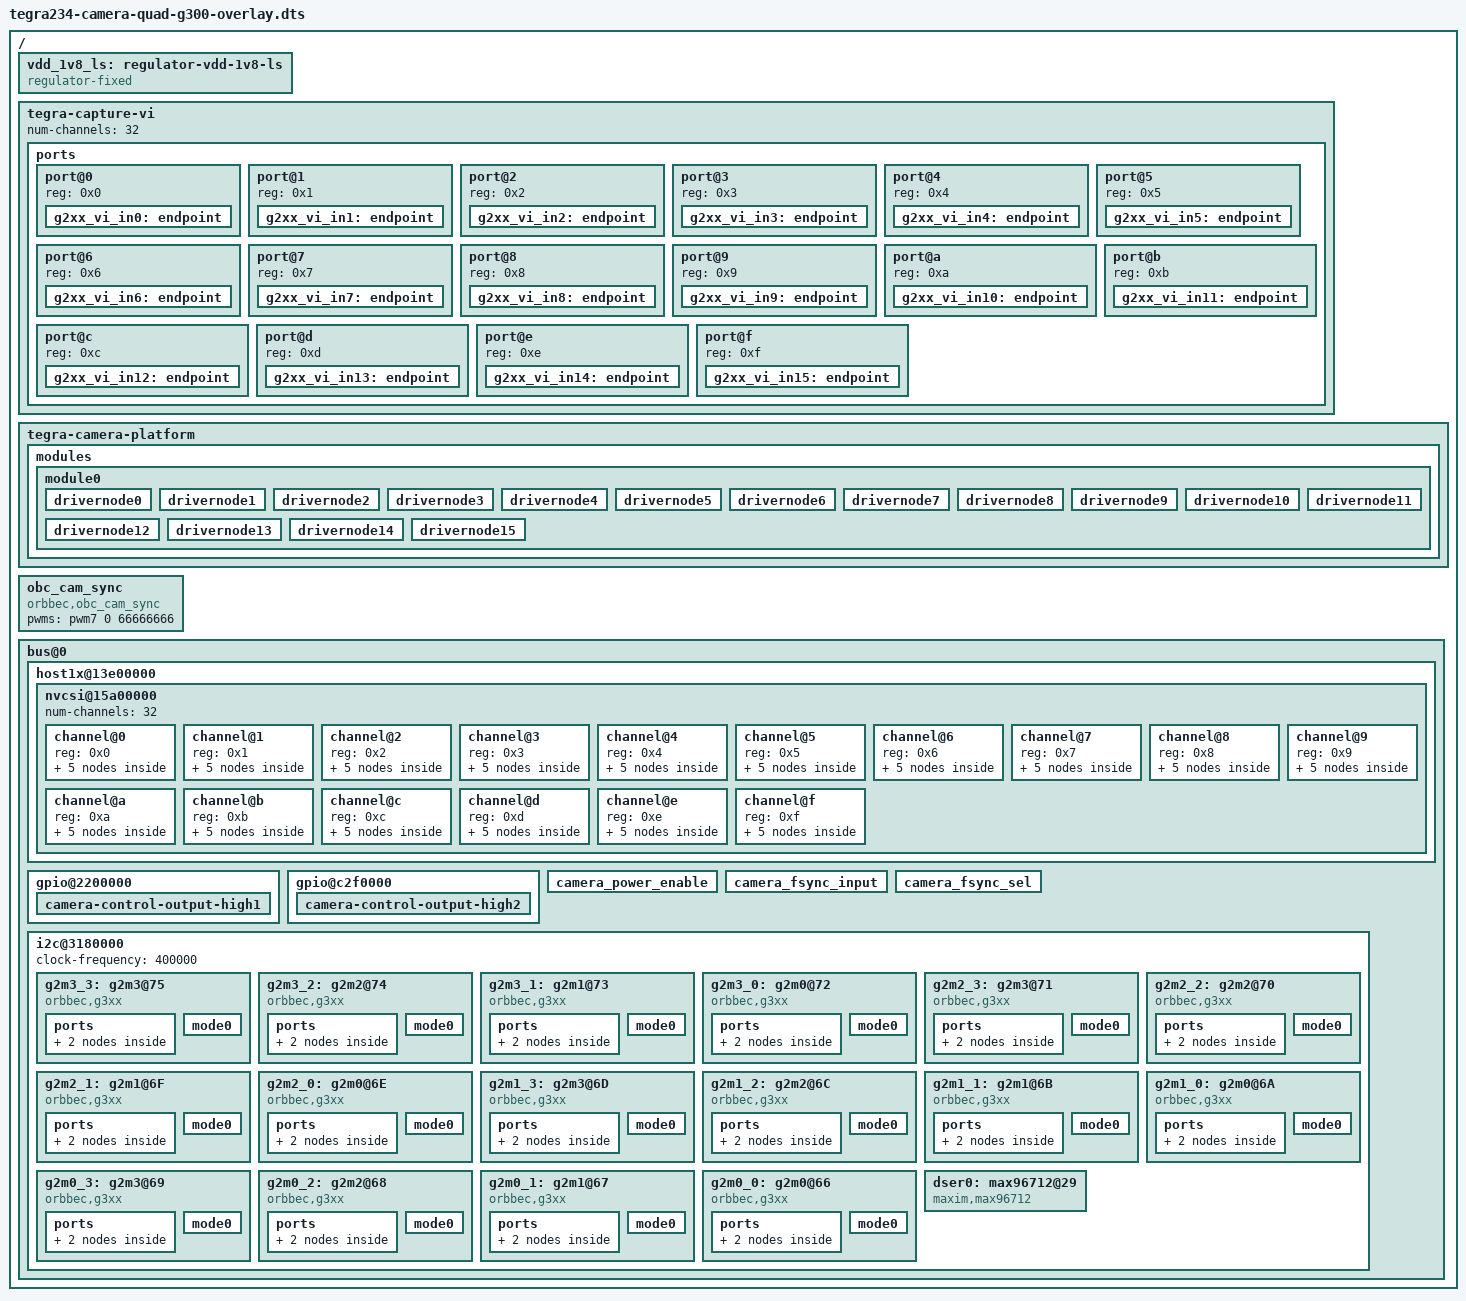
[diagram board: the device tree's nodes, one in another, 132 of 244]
// SPDX-License-Identifier: GPL-2.0-only
// SPDX-FileCopyrightText: Copyright (c) 2024-2029, Orbbec CORPORATION.  All rights reserved.


#include <dt-bindings/clock/tegra234-clock.h>
#include <dt-bindings/gpio/tegra234-gpio.h>
#include <dt-bindings/tegra234-p3767-0000-common.h>
#include <dt-bindings/pinctrl/pinctrl-tegra.h>
//MFP9 TEGRA234 MAIN GPIO(AC，0)
//MFP10  TEGRA234 MAIN GPIO(Z，7)
//MPP2   TEGRA_AON_GPIO(G, 6)

#define CAM0_RST_L	TEGRA234_AON_GPIO(CC, 3)
#define CAM0_PWDN   TEGRA234_MAIN_GPIO(H, 6)
#define PWR_EN      TEGRA234_MAIN_GPIO(AC, 7)
#define SYNC_OUT   	TEGRA234_MAIN_GPIO(G, 6)
#define SYNC_IN    	TEGRA234_MAIN_GPIO(AC, 4) //
#define SYNC_SEL   	TEGRA234_MAIN_GPIO(AC, 2)
#define PPS_TRIGGER	TEGRA234_MAIN_GPIO(AC, 0) //
#define CAMERA_I2C_MUX_BUS(x) (0x1E + x)
/{
	vdd_1v8_ls: regulator-vdd-1v8-ls {
			compatible = "regulator-fixed";
			regulator-name = "VDD_1V8_LS";
			regulator-min-microvolt = <1800000>;
			regulator-max-microvolt = <1800000>;
			regulator-always-on;
	};


	/* Orbbec Camera configuration */
	tegra-capture-vi {
		num-channels = <32>;
		ports {
			status = "okay";
			#address-cells = <1>;
			#size-cells = <0>;

			port@0 {
				reg = <0x0>;
				status = "okay";
				g2xx_vi_in0: endpoint {
					status = "okay";
					vc-id = <0>;
					port-index = <0>; //0
					bus-width = <2>;
					remote-endpoint = <&g2xx_csi_out0>;
				};
			};
			port@1 {
				reg = <0x1>;
				status = "okay";
				g2xx_vi_in1: endpoint {
					status = "okay";
					vc-id = <1>;
					port-index = <0>; //0
					bus-width = <2>;
					remote-endpoint = <&g2xx_csi_out1>;
				};
			};
			port@2 {
				reg = <0x2>;
				status = "okay";
				g2xx_vi_in2: endpoint {
					status = "okay";
					vc-id = <2>;
					port-index = <0>; //0
					bus-width = <2>;
					remote-endpoint = <&g2xx_csi_out2>;
				};
			};
			port@3 {
				reg = <0x3>;
				status = "okay";
				g2xx_vi_in3: endpoint {
					status = "okay";
					vc-id = <3>;
					port-index = <0>; //0
					bus-width = <2>;
					remote-endpoint = <&g2xx_csi_out3>;
				};
			};

			port@4 {
				reg = <0x4>;
				status = "okay";
				g2xx_vi_in4: endpoint {
					status = "okay";
					vc-id = <2>;
					port-index = <1>; //1
					bus-width = <2>;
					remote-endpoint = <&g2xx_csi_out4>;
				};
			};
			port@5 {
				reg = <0x5>;
				status = "okay";
				g2xx_vi_in5: endpoint {
					status = "okay";
					vc-id = <3>;
					port-index = <1>; //1
					bus-width = <2>;
					remote-endpoint = <&g2xx_csi_out5>;
				};
			};
			port@6 {
				reg = <0x6>;
				status = "okay";
				g2xx_vi_in6: endpoint {
					status = "okay";
					vc-id = <0>;
					port-index = <1>; //1
					bus-width = <2>;
					remote-endpoint = <&g2xx_csi_out6>;
				};
			};
			port@7 {
				reg = <0x7>;
				status = "okay";
				g2xx_vi_in7: endpoint {
					status = "okay";
					vc-id = <1>;
					port-index = <1>; //1
					bus-width = <2>;
					remote-endpoint = <&g2xx_csi_out7>;
				};
			};

			port@8 {
				reg = <0x8>;
				status = "okay";
				g2xx_vi_in8: endpoint {
					status = "okay";
					vc-id = <0>;
					port-index = <2>; //2
					bus-width = <2>;
					remote-endpoint = <&g2xx_csi_out8>;
				};
			};
			port@9 {
				reg = <0x9>;
				status = "okay";
				g2xx_vi_in9: endpoint {
					status = "okay";
					vc-id = <1>;
					port-index = <2>; //2
					bus-width = <2>;
					remote-endpoint = <&g2xx_csi_out9>;
				};
			};
			port@a {
				reg = <0xa>;
				status = "okay";
				g2xx_vi_in10: endpoint {
					status = "okay";
					vc-id = <2>;
					port-index = <2>; //2
					bus-width = <2>;
					remote-endpoint = <&g2xx_csi_out10>;
				};
			};
			port@b {
				reg = <0xb>;
				status = "okay";
				g2xx_vi_in11: endpoint {
					status = "okay";
					vc-id = <3>;
					port-index = <2>; //2
					bus-width = <2>;
					remote-endpoint = <&g2xx_csi_out11>;
				};
			};

			port@c {
				reg = <0xc>;
				status = "okay";
				g2xx_vi_in12: endpoint {
					status = "okay";
					vc-id = <2>;
					port-index = <3>; //3
					bus-width = <2>;
					remote-endpoint = <&g2xx_csi_out12>;
				};
			};

			port@d {
				reg = <0xd>;
				status = "okay";
				g2xx_vi_in13: endpoint {
					status = "okay";
					vc-id = <3>;
					port-index = <3>; //3
					bus-width = <2>;
					remote-endpoint = <&g2xx_csi_out13>;
				};
			};
			port@e {
				reg = <0xe>;
				status = "okay";
				g2xx_vi_in14: endpoint {
					status = "okay";
					vc-id = <0>;
					port-index = <3>; //3
					bus-width = <2>;
					remote-endpoint = <&g2xx_csi_out14>;
				};
			};
			port@f {
				reg = <0xf>;
				status = "okay";
				g2xx_vi_in15: endpoint {
					status = "okay";
					vc-id = <1>;
					port-index = <3>; //3
					bus-width = <2>;
					remote-endpoint = <&g2xx_csi_out15>;
				};
			};
		};
	};

	tegra-camera-platform {
		#if 0
		compatible = "nvidia, tegra-camera-platform";
		num_csi_lanes = <16>;
		max_lane_speed = <20000000>;
		min_bits_per_pixel = <8>;
		vi_peak_byte_per_pixel = <2>;
		vi_bw_margin_pct = <25>;
		isp_peak_byte_per_pixel = <5>;
		isp_bw_margin_pct = <25>;
		#endif
		modules {
			status = "okay";
			module0 {
				status = "okay";
				badge = "g2xx_0";
				position = "bottomleft";
				orientation = "1";

				drivernode0 {
					status = "okay";
					/* Declare PCL support driver (classically known as guid)  */
					pcl_id = "v4l2_sensor";
					/* Declare the device-tree hierarchy to driver instance */
					sysfs-device-tree = "/sys/firmware/devicetree/base/bus@0/i2c@3180000/g2m0@66";
				};

				drivernode1 {
					status = "okay";
					/* Declare PCL support driver (classically known as guid)  */
					pcl_id = "v4l2_sensor";
					/* Declare the device-tree hierarchy to driver instance */
					sysfs-device-tree = "/sys/firmware/devicetree/base/bus@0/i2c@3180000/g2m1@67";
				};

				drivernode2 {
					status = "okay";
					/* Declare PCL support driver (classically known as guid)  */
					pcl_id = "v4l2_sensor";
					/* Declare the device-tree hierarchy to driver instance */
					sysfs-device-tree = "/sys/firmware/devicetree/base/bus@0/i2c@3180000/g2m2@68";
				};

				drivernode3 {
					status = "okay";
					/* Declare PCL support driver (classically known as guid)  */
					pcl_id = "v4l2_sensor";
					/* Declare the device-tree hierarchy to driver instance */
					sysfs-device-tree = "/sys/firmware/devicetree/base/bus@0/i2c@3180000/g2m3@69";
				};

				drivernode4 {
					status = "okay";
					/* Declare PCL support driver (classically known as guid)  */
					pcl_id = "v4l2_sensor";
					/* Declare the device-tree hierarchy to driver instance */
					sysfs-device-tree = "/sys/firmware/devicetree/base/bus@0/i2c@3180000/g2m0@6A";
				};

				drivernode5 {
					status = "okay";
					/* Declare PCL support driver (classically known as guid)  */
					pcl_id = "v4l2_sensor";
					/* Declare the device-tree hierarchy to driver instance */
					sysfs-device-tree = "/sys/firmware/devicetree/base/bus@0/i2c@3180000/g2m1@6B";
				};

				drivernode6 {
					status = "okay";
					/* Declare PCL support driver (classically known as guid)  */
					pcl_id = "v4l2_sensor";
					/* Declare the device-tree hierarchy to driver instance */
					sysfs-device-tree = "/sys/firmware/devicetree/base/bus@0/i2c@3180000/g2m2@6C";
				};

				drivernode7 {
					status = "okay";
					/* Declare PCL support driver (classically known as guid)  */
					pcl_id = "v4l2_sensor";
					/* Declare the device-tree hierarchy to driver instance */
					sysfs-device-tree = "/sys/firmware/devicetree/base/bus@0/i2c@3180000/g2m3@6D";
				};

				drivernode8 {
					status = "okay";
					/* Declare PCL support driver (classically known as guid)  */
					pcl_id = "v4l2_sensor";
					/* Declare the device-tree hierarchy to driver instance */
					sysfs-device-tree = "/sys/firmware/devicetree/base/bus@0/i2c@3180000/g2m0@6E";
				};

				drivernode9 {
					status = "okay";
					/* Declare PCL support driver (classically known as guid)  */
					pcl_id = "v4l2_sensor";
					/* Declare the device-tree hierarchy to driver instance */
					sysfs-device-tree = "/sys/firmware/devicetree/base/bus@0/i2c@3180000/g2m1@6F";
				};

				drivernode10 {
					status = "okay";
					/* Declare PCL support driver (classically known as guid)  */
					pcl_id = "v4l2_sensor";
					/* Declare the device-tree hierarchy to driver instance */
					sysfs-device-tree = "/sys/firmware/devicetree/base/bus@0/i2c@3180000/g2m2@70";
				};

				drivernode11 {
					status = "okay";
					/* Declare PCL support driver (classically known as guid)  */
					pcl_id = "v4l2_sensor";
					/* Declare the device-tree hierarchy to driver instance */
					sysfs-device-tree = "/sys/firmware/devicetree/base/bus@0/i2c@3180000/g2m3@71";
				};

				drivernode12 {
					status = "okay";
					/* Declare PCL support driver (classically known as guid)  */
					pcl_id = "v4l2_sensor";
					/* Declare the device-tree hierarchy to driver instance */
					sysfs-device-tree = "/sys/firmware/devicetree/base/bus@0/i2c@3180000/g2m0@72";
				};

				drivernode13 {
					status = "okay";
					/* Declare PCL support driver (classically known as guid)  */
					pcl_id = "v4l2_sensor";
					/* Declare the device-tree hierarchy to driver instance */
					sysfs-device-tree = "/sys/firmware/devicetree/base/bus@0/i2c@3180000/g2m1@73";
				};

				drivernode14 {
					status = "okay";
					/* Declare PCL support driver (classically known as guid)  */
					pcl_id = "v4l2_sensor";
					/* Declare the device-tree hierarchy to driver instance */
					sysfs-device-tree = "/sys/firmware/devicetree/base/bus@0/i2c@3180000/g2m2@74";
				};

				drivernode15 {
					status = "okay";
					/* Declare PCL support driver (classically known as guid)  */
					pcl_id = "v4l2_sensor";
					/* Declare the device-tree hierarchy to driver instance */
					sysfs-device-tree = "/sys/firmware/devicetree/base/bus@0/i2c@3180000/g2m3@75";
				};
			};
		};
	};

	obc_cam_sync {
		compatible = "orbbec,obc_cam_sync";
		//sync-in-gpios = <&gpio SYNC_IN GPIO_ACTIVE_HIGH>;
		//sync-out-gpios = <&gpio_aon SYNC_OUT GPIO_ACTIVE_HIGH>;  //Use hrtimer to generate trigger signals
		pwms = <&pwm7 0 66666666>; //33333333>; //Use PWM to generate trigger signals, Default PWM mode, if use hrtimer comment out this line
	};
	bus@0 {
		/* NVCSI configuration */
		host1x@13e00000 {
			nvcsi@15a00000 {
				#address-cells = <1>;
				#size-cells = <0>;

				num-channels = <32>;

				channel@0 {
					reg = <0x0>;
					status = "okay";
					ports {
						status = "okay";
						#address-cells = <1>;
						#size-cells = <0>;
						port@0 {
							reg = <0>;
							status = "okay";
							g2xx_csi_in0: endpoint@0 {
								status = "okay";
								port-index = <0>; //0
								bus-width = <2>;
								remote-endpoint = <&g2m0_0_out>;
							};
						};
						port@1 {
							reg = <1>;
							status = "okay";
							g2xx_csi_out0: endpoint@1 {
								status = "okay";
								remote-endpoint = <&g2xx_vi_in0>;
							};
						};
					};
				};
				channel@1 {
					reg = <0x1>;
					status = "okay";
					ports {
						status = "okay";
						#address-cells = <1>;
						#size-cells = <0>;
						port@0 {
							reg = <0>;
							status = "okay";
							g2xx_csi_in1: endpoint@2 {
								status = "okay";
								port-index = <0>; //0
								bus-width = <2>;
								remote-endpoint = <&g2m0_1_out>;
							};
						};
						port@1 {
							reg = <1>;
							status = "okay";
							g2xx_csi_out1: endpoint@3 {
								status = "okay";
								remote-endpoint = <&g2xx_vi_in1>;
							};
						};
					};
				};
				channel@2 {
					reg = <0x2>;
					status = "okay";
					ports {
						status = "okay";
						#address-cells = <1>;
						#size-cells = <0>;
						port@0 {
							reg = <0>;
							status = "okay";
							g2xx_csi_in2: endpoint@4 {
								status = "okay";
								port-index = <0>; //0
								bus-width = <2>;
								remote-endpoint = <&g2m0_2_out>;
							};
						};
						port@1 {
							reg = <1>;
							status = "okay";
							g2xx_csi_out2: endpoint@5 {
								status = "okay";
								remote-endpoint = <&g2xx_vi_in2>;
							};
						};
					};
				};
				channel@3 {
					reg = <0x3>;
					status = "okay";
					ports {
						status = "okay";
						#address-cells = <1>;
						#size-cells = <0>;
						port@0 {
							reg = <0>;
							status = "okay";
							g2xx_csi_in3: endpoint@6 {
								status = "okay";
								port-index = <0>; //0
								bus-width = <2>;
								remote-endpoint = <&g2m0_3_out>;
							};
						};
						port@1 {
							reg = <1>;
							status = "okay";
							g2xx_csi_out3: endpoint@7 {
								status = "okay";
								remote-endpoint = <&g2xx_vi_in3>;
							};
						};
					};
				};

				channel@4 {
					reg = <0x4>;
					status = "okay";
					ports {
						status = "okay";
						#address-cells = <1>;
						#size-cells = <0>;
						port@0 {
							reg = <0>;
							status = "okay";
							g2xx_csi_in4: endpoint@8 {
								status = "okay";
								port-index = <1>; //1
								bus-width = <2>;
								remote-endpoint = <&g2m1_0_out>;
							};
						};
						port@1 {
							reg = <1>;
							status = "okay";
							g2xx_csi_out4: endpoint@9 {
								status = "okay";
								remote-endpoint = <&g2xx_vi_in4>;
							};
						};
					};
				};
				channel@5 {
					reg = <0x5>;
					status = "okay";
					ports {
						status = "okay";
						#address-cells = <1>;
						#size-cells = <0>;
						port@0 {
							reg = <0>;
							status = "okay";
							g2xx_csi_in5: endpoint@10 {
								status = "okay";
								port-index = <1>; //1
								bus-width = <2>;
								remote-endpoint = <&g2m1_1_out>;
							};
						};
						port@1 {
							reg = <1>;
							status = "okay";
							g2xx_csi_out5: endpoint@11 {
								status = "okay";
								remote-endpoint = <&g2xx_vi_in5>;
							};
						};
					};
				};
				channel@6 {
					reg = <0x6>;
					status = "okay";
					ports {
						status = "okay";
						#address-cells = <1>;
						#size-cells = <0>;
						port@0 {
							reg = <0>;
							status = "okay";
							g2xx_csi_in6: endpoint@12 {
								status = "okay";
								port-index = <1>; //1
								bus-width = <2>;
								remote-endpoint = <&g2m1_2_out>;
							};
						};
						port@1 {
							reg = <1>;
							status = "okay";
							g2xx_csi_out6: endpoint@13 {
								status = "okay";
								remote-endpoint = <&g2xx_vi_in6>;
							};
						};
					};
				};
				channel@7 {
					reg = <0x7>;
					status = "okay";
					ports {
						status = "okay";
						#address-cells = <1>;
						#size-cells = <0>;
						port@0 {
							reg = <0>;
							status = "okay";
							g2xx_csi_in7: endpoint@14 {
								status = "okay";
								port-index = <1>; //1
								bus-width = <2>;
								remote-endpoint = <&g2m1_3_out>;
							};
						};
						port@1 {
							reg = <1>;
							status = "okay";
							g2xx_csi_out7: endpoint@15 {
								status = "okay";
								remote-endpoint = <&g2xx_vi_in7>;
							};
						};
					};
				};

				channel@8 {
					reg = <0x8>;
					status = "okay";
					ports {
						status = "okay";
						#address-cells = <1>;
						#size-cells = <0>;
						port@0 {
							reg = <0>;
							status = "okay";
							g2xx_csi_in8: endpoint@16 {
								status = "okay";
								port-index = <2>; //2
								bus-width = <2>;
								remote-endpoint = <&g2m2_0_out>;
							};
						};
						port@1 {
							reg = <1>;
							status = "okay";
							g2xx_csi_out8: endpoint@17 {
								status = "okay";
								remote-endpoint = <&g2xx_vi_in8>;
							};
						};
					};
				};
				channel@9 {
					reg = <0x9>;
					status = "okay";
					ports {
						status = "okay";
						#address-cells = <1>;
						#size-cells = <0>;
						port@0 {
							reg = <0>;
							status = "okay";
							g2xx_csi_in9: endpoint@18 {
								status = "okay";
								port-index = <2>; //2
								bus-width = <2>;
								remote-endpoint = <&g2m2_1_out>;
							};
						};
						port@1 {
							reg = <1>;
							status = "okay";
							g2xx_csi_out9: endpoint@19 {
								status = "okay";
								remote-endpoint = <&g2xx_vi_in9>;
							};
						};
					};
				};
				channel@a {
					reg = <0xa>;
					status = "okay";
					ports {
						status = "okay";
						#address-cells = <1>;
						#size-cells = <0>;
						port@0 {
							reg = <0>;
							status = "okay";
							g2xx_csi_in10: endpoint@20 {
								status = "okay";
								port-index = <2>; //2
								bus-width = <2>;
								remote-endpoint = <&g2m2_2_out>;
							};
						};
						port@1 {
							reg = <1>;
							status = "okay";
							g2xx_csi_out10: endpoint@21 {
								status = "okay";
								remote-endpoint = <&g2xx_vi_in10>;
							};
						};
					};
				};
				channel@b {
					reg = <0xb>;
					status = "okay";
					ports {
						status = "okay";
						#address-cells = <1>;
						#size-cells = <0>;
						port@0 {
							reg = <0>;
							status = "okay";
							g2xx_csi_in11: endpoint@22 {
								status = "okay";
								port-index = <2>; //2
								bus-width = <2>;
								remote-endpoint = <&g2m2_3_out>;
							};
						};
						port@1 {
							reg = <1>;
							status = "okay";
							g2xx_csi_out11: endpoint@23 {
								status = "okay";
								remote-endpoint = <&g2xx_vi_in11>;
							};
						};
					};
				};

				channel@c {
					reg = <0xc>;
					status = "okay";
					ports {
						status = "okay";
						#address-cells = <1>;
						#size-cells = <0>;
						port@0 {
							reg = <0>;
							status = "okay";
							g2xx_csi_in12: endpoint@24 {
								status = "okay";
								port-index = <3>; //3
								bus-width = <2>;
								remote-endpoint = <&g2m3_0_out>;
							};
						};
						port@1 {
							reg = <1>;
							status = "okay";
							g2xx_csi_out12: endpoint@25 {
								status = "okay";
								remote-endpoint = <&g2xx_vi_in12>;
							};
						};
					};
				};
				channel@d {
					reg = <0xd>;
					status = "okay";
					ports {
						status = "okay";
						#address-cells = <1>;
						#size-cells = <0>;
						port@0 {
							reg = <0>;
							status = "okay";
							g2xx_csi_in13: endpoint@26 {
								status = "okay";
								port-index = <3>; //3
								bus-width = <2>;
								remote-endpoint = <&g2m3_1_out>;
							};
						};
						port@1 {
							reg = <1>;
							status = "okay";
							g2xx_csi_out13: endpoint@27 {
								status = "okay";
								remote-endpoint = <&g2xx_vi_in13>;
							};
						};
					};
				};
				channel@e {
					reg = <0xe>;
					status = "okay";
					ports {
						status = "okay";
						#address-cells = <1>;
						#size-cells = <0>;
						port@0 {
							reg = <0>;
							status = "okay";
							g2xx_csi_in14: endpoint@28 {
								status = "okay";
								port-index = <3>; //3
								bus-width = <2>;
								remote-endpoint = <&g2m3_2_out>;
							};
						};
						port@1 {
							reg = <1>;
							status = "okay";
							g2xx_csi_out14: endpoint@29 {
								status = "okay";
								remote-endpoint = <&g2xx_vi_in14>;
							};
						};
					};
				};
				channel@f {
					reg = <0xf>;
					status = "okay";
					ports {
						status = "okay";
						#address-cells = <1>;
						#size-cells = <0>;
						port@0 {
							reg = <0>;
							status = "okay";
							g2xx_csi_in15: endpoint@30 {
								status = "okay";
								port-index = <3>; //3
								bus-width = <2>;
								remote-endpoint = <&g2m3_3_out>;
							};
						};
						port@1 {
							reg = <1>;
							status = "okay";
							g2xx_csi_out15: endpoint@31 {
								status = "okay";
								remote-endpoint = <&g2xx_vi_in15>;
							};
						};
					};
				};
			};
		};

		/* GPIO configuration */
		gpio@2200000 {
			camera-control-output-high1 {
				gpio-hog;
				output-high;
				gpios = <CAM0_PWDN 0>;
				label = "cam0-pwdn";
			};
		};

		gpio@c2f0000 {
			camera-control-output-high2 {
				gpio-hog;
				output-high;
				gpios = <CAM0_RST_L 0>;
				label = "cam0-rst";
			};
		};


		camera_power_enable {
			gpio-hog;
			output-high;
			gpios = <PWR_EN GPIO_ACTIVE_HIGH>;
			label = "cam-pwr-en";
		};

		camera_fsync_input {
			gpio-hog;
			input;
			gpios = <SYNC_OUT 0>;
			label = "fsync-in";
		};

		camera_fsync_sel {
			gpio-hog;
			output-high;
			gpios = <SYNC_SEL 0>;
			label = "fsync-sel";
		};

		/* I2C configuration */
		i2c@3180000 {
			status = "okay";
			clock-frequency = <400000>;

			#address-cells = <1>;
			#size-cells = <0>;

			g2m3_3: g2m3@75 {
				status = "okay";
				reg = <0x75>;
				compatible = "orbbec,g3xx";
				use_sensor_mode_id = "true";
				vcc-supply = <&vdd_1v8_ls>;
				cam-type = "IR_R";
				dser-link-port = "d";
				st-vc = <3>;
				vc-id = <1>;
				orbbec_cam_num = <3>;
				nvidia,gmsl-dser-device = <&dser0>;
				pps-gpios = <&gpio PPS_TRIGGER GPIO_ACTIVE_LOW>;
				ports {
					#address-cells = <1>;
					#size-cells = <0>;

					port@0 {
						reg = <0>;
						g2m3_3_out: endpoint {
							vc-id = <1>;
							port-index = <3>;
							bus-width = <2>;
							remote-endpoint = <&g2xx_csi_in15>;
						};
					};
				};
				mode0 {
					pixel_t = "grey_y8";
					num_lanes = "4";
					csi_pixel_bit_depth = "8";
					active_w = "1280";
					active_h = "720";
					tegra_sinterface = "serial_d";
					mclk_khz = "24000";
					pix_clk_hz = "750000000";
					serdes_pix_clk_hz = "750000000";
					discontinuous_clk = "no";
					dpcm_enable = "false";
					cil_settletime = "0";
					line_length = "1280";
					mclk_multiplier = "15.625";
					embedded_metadata_height = "1";
					vc_id = "1";
				};
			};
			g2m3_2: g2m2@74 {
				status = "okay";
				reg = <0x74>;
				compatible = "orbbec,g3xx";
				use_sensor_mode_id = "true";
				vcc-supply = <&vdd_1v8_ls>;
				cam-type = "IR_L";
				dser-link-port = "d";
				st-vc = <2>;
				vc-id = <0>;
				orbbec_cam_num = <3>;
				nvidia,gmsl-dser-device = <&dser0>;
				pps-gpios = <&gpio PPS_TRIGGER GPIO_ACTIVE_LOW>;
				ports {
					#address-cells = <1>;
					#size-cells = <0>;

					port@0 {
						reg = <0>;
						g2m3_2_out: endpoint {
							vc-id = <0>;
							port-index = <3>;
							bus-width = <2>;
							remote-endpoint = <&g2xx_csi_in14>;
						};
					};
				};
				mode0 {
					pixel_t = "grey_y8";
					num_lanes = "4";
					csi_pixel_bit_depth = "8";
					active_w = "1280";
					active_h = "720";
					tegra_sinterface = "serial_d";
					mclk_khz = "24000";
					pix_clk_hz = "750000000";
					serdes_pix_clk_hz = "750000000";
					discontinuous_clk = "no";
					dpcm_enable = "false";
					cil_settletime = "0";
					line_length = "1280";
					mclk_multiplier = "15.625";
					embedded_metadata_height = "1";
					vc_id = "0";
				};
			};
			g2m3_1: g2m1@73 {
				status = "okay";
				reg = <0x73>;
				compatible = "orbbec,g3xx";
				use_sensor_mode_id = "true";
				vcc-supply = <&vdd_1v8_ls>;
				cam-type = "RGB";
				dser-link-port = "d";
				st-vc = <1>;
				vc-id = <3>;
				orbbec_cam_num = <3>;
				nvidia,gmsl-dser-device = <&dser0>;
				pps-gpios = <&gpio PPS_TRIGGER GPIO_ACTIVE_LOW>;
				ports {
					#address-cells = <1>;
					#size-cells = <0>;

					port@0 {
						reg = <0>;
						g2m3_1_out: endpoint {
							vc-id = <3>;
							port-index = <3>;
							bus-width = <2>;
							remote-endpoint = <&g2xx_csi_in13>;
						};
					};
				};
				mode0 {
					pixel_t = "yuv_yvyu16";
					num_lanes = "4";
					csi_pixel_bit_depth = "16";
					active_w = "1280";
					active_h = "720";
					tegra_sinterface = "serial_d";
					mclk_khz = "24000";
					pix_clk_hz = "375000000";
					serdes_pix_clk_hz = "375000000";
					discontinuous_clk = "no";
					dpcm_enable = "false";
					cil_settletime = "0";
					line_length = "1280";
					mclk_multiplier = "15.625";
					embedded_metadata_height = "1";
					vc_id = "3";
				};
			};
			g2m3_0: g2m0@72 {
				status = "okay";
				reg = <0x72>;
				compatible = "orbbec,g3xx";
				use_sensor_mode_id = "true";
				vcc-supply = <&vdd_1v8_ls>;
				cam-type = "Depth";
				dser-link-port = "d";
				st-vc = <0>;
				vc-id = <2>;
				orbbec_cam_num = <3>;
				nvidia,gmsl-dser-device = <&dser0>;
				pps-gpios = <&gpio PPS_TRIGGER GPIO_ACTIVE_LOW>;
				ports {
					#address-cells = <1>;
					#size-cells = <0>;

					port@0 {
						reg = <0>;
						g2m3_0_out: endpoint {
							vc-id = <2>;
							port-index = <3>;
							bus-width = <2>;
							remote-endpoint = <&g2xx_csi_in12>;
						};
					};
				};
				mode0 {
					pixel_t = "yuv_yvyu16";
					num_lanes = "4";
					csi_pixel_bit_depth = "16";
					active_w = "1280";
					active_h = "720";
					tegra_sinterface = "serial_d";
					mclk_khz = "24000";
					pix_clk_hz = "375000000";
					serdes_pix_clk_hz = "375000000";
					discontinuous_clk = "no";
					dpcm_enable = "false";
					cil_settletime = "0";
					line_length = "1280";
					mclk_multiplier = "15.625";
					embedded_metadata_height = "1";
					vc_id = "2";
				};
			};

			g2m2_3: g2m3@71 {
				status = "okay";
				reg = <0x71>;
				compatible = "orbbec,g3xx";
				use_sensor_mode_id = "true";
				vcc-supply = <&vdd_1v8_ls>;
				cam-type = "IR_R";
				dser-link-port = "c";
				st-vc = <3>;
				vc-id = <3>;
				orbbec_cam_num = <2>;
				nvidia,gmsl-dser-device = <&dser0>;
				pps-gpios = <&gpio PPS_TRIGGER GPIO_ACTIVE_LOW>;
				ports {
					#address-cells = <1>;
					#size-cells = <0>;

					port@0 {
						reg = <0>;
						g2m2_3_out: endpoint {
							vc-id = <3>;
							port-index = <2>; //2
							bus-width = <2>;
							remote-endpoint = <&g2xx_csi_in11>;
						};
					};
				};
				mode0 {
					pixel_t = "grey_y8";
					num_lanes = "4";
					csi_pixel_bit_depth = "8";
					active_w = "1280";
					active_h = "720";
					tegra_sinterface = "serial_c";
					mclk_khz = "24000";
					pix_clk_hz = "750000000";
					serdes_pix_clk_hz = "750000000";
					discontinuous_clk = "no";
					dpcm_enable = "false";
					cil_settletime = "0";
					line_length = "1280";
					mclk_multiplier = "15.625";
					embedded_metadata_height = "1";
					vc_id = "3";
				};
			};
			g2m2_2: g2m2@70 {
				status = "okay";
				reg = <0x70>;
				compatible = "orbbec,g3xx";
				use_sensor_mode_id = "true";
				vcc-supply = <&vdd_1v8_ls>;
				cam-type = "IR_L";
				dser-link-port = "c";
				st-vc = <2>;
				vc-id = <2>;
				orbbec_cam_num = <2>;
				nvidia,gmsl-dser-device = <&dser0>;
				pps-gpios = <&gpio PPS_TRIGGER GPIO_ACTIVE_LOW>;
				ports {
					#address-cells = <1>;
					#size-cells = <0>;

					port@0 {
						reg = <0>;
						g2m2_2_out: endpoint {
							vc-id = <2>;
							port-index = <2>; //2
							bus-width = <2>;
							remote-endpoint = <&g2xx_csi_in10>;
						};
					};
				};
				mode0 {
					pixel_t = "grey_y8";
					num_lanes = "4";
					csi_pixel_bit_depth = "8";
					active_w = "1280";
					active_h = "720";
					tegra_sinterface = "serial_c";
					mclk_khz = "24000";
					pix_clk_hz = "750000000";
					serdes_pix_clk_hz = "750000000";
					discontinuous_clk = "no";
					dpcm_enable = "false";
					cil_settletime = "0";
					line_length = "1280";
					mclk_multiplier = "15.625";
					embedded_metadata_height = "1";
					vc_id = "2";
				};
			};
			g2m2_1: g2m1@6F {
				status = "okay";
				reg = <0x6F>;
				compatible = "orbbec,g3xx";
				use_sensor_mode_id = "true";
				vcc-supply = <&vdd_1v8_ls>;
				cam-type = "RGB";
				dser-link-port = "c";
				st-vc = <1>;
				vc-id = <1>;
				orbbec_cam_num = <2>;
				nvidia,gmsl-dser-device = <&dser0>;
				pps-gpios = <&gpio PPS_TRIGGER GPIO_ACTIVE_LOW>;
				ports {
					#address-cells = <1>;
					#size-cells = <0>;

					port@0 {
						reg = <0>;
						g2m2_1_out: endpoint {
							vc-id = <1>;
							port-index = <2>; //2
							bus-width = <2>;
							remote-endpoint = <&g2xx_csi_in9>;
						};
					};
				};
				mode0 {
					pixel_t = "yuv_yvyu16";
					num_lanes = "4";
					csi_pixel_bit_depth = "16";
					active_w = "1280";
					active_h = "720";
					tegra_sinterface = "serial_c";
					mclk_khz = "24000";
					pix_clk_hz = "375000000";
					serdes_pix_clk_hz = "375000000";
					discontinuous_clk = "no";
					dpcm_enable = "false";
					cil_settletime = "0";
					line_length = "1280";
					mclk_multiplier = "15.625";
					embedded_metadata_height = "1"; 
					vc_id = "1";
				};
			};
			g2m2_0: g2m0@6E {
				status = "okay";
				reg = <0x6E>;
				compatible = "orbbec,g3xx";
				use_sensor_mode_id = "true";
				vcc-supply = <&vdd_1v8_ls>;
				cam-type = "Depth";
				dser-link-port = "c";
				st-vc = <0>;   				/**< Default sensor virtual channel. */
				vc-id = <0>;				/**< Destination virtual channel (user-defined). */
				orbbec_cam_num = <2>;
				nvidia,gmsl-dser-device = <&dser0>;
				pps-gpios = <&gpio PPS_TRIGGER GPIO_ACTIVE_LOW>;
				ports {
					#address-cells = <1>;
					#size-cells = <0>;

					port@0 {
						reg = <0>;
						g2m2_0_out: endpoint {
							vc-id = <0>;
							port-index = <2>; //2
							bus-width = <2>;
							remote-endpoint = <&g2xx_csi_in8>;
						};
					};
				};
				mode0 {
					pixel_t = "yuv_yvyu16";
					num_lanes = "4";
					csi_pixel_bit_depth = "16";
					active_w = "1280";
					active_h = "720";
					tegra_sinterface = "serial_c";
					mclk_khz = "24000";
					pix_clk_hz = "375000000";
					serdes_pix_clk_hz = "375000000";
					discontinuous_clk = "no";
					dpcm_enable = "false";
					cil_settletime = "0";
					line_length = "1280";
					mclk_multiplier = "15.625";
					embedded_metadata_height = "1"; 
					vc_id = "0";
				};
			};

			g2m1_3: g2m3@6D {
				status = "okay";
				reg = <0x6D>;
				compatible = "orbbec,g3xx";
				use_sensor_mode_id = "true";
				vcc-supply = <&vdd_1v8_ls>;
				cam-type = "IR_R";
				dser-link-port = "b";
				st-vc = <3>;
				vc-id = <1>;
				orbbec_cam_num = <1>;
				nvidia,gmsl-dser-device = <&dser0>;
				pps-gpios = <&gpio PPS_TRIGGER GPIO_ACTIVE_LOW>;
				ports {
					#address-cells = <1>;
					#size-cells = <0>;

					port@0 {
						reg = <0>;
						g2m1_3_out: endpoint {
							vc-id = <1>;
							port-index = <1>; //1
							bus-width = <2>;
							remote-endpoint = <&g2xx_csi_in7>;
						};
					};
				};
				mode0 {
					pixel_t = "grey_y8";
					num_lanes = "4";
					csi_pixel_bit_depth = "8";
					active_w = "1280";
					active_h = "720";
					tegra_sinterface = "serial_b";
					mclk_khz = "24000";
					pix_clk_hz = "750000000";
					serdes_pix_clk_hz = "750000000";
					discontinuous_clk = "no";
					dpcm_enable = "false";
					cil_settletime = "0";
					line_length = "1280";
					mclk_multiplier = "15.625";
					embedded_metadata_height = "1";
					vc_id = "1";
				};
			};
			g2m1_2: g2m2@6C {
				status = "okay";
				reg = <0x6C>;
				compatible = "orbbec,g3xx";
				use_sensor_mode_id = "true";
				vcc-supply = <&vdd_1v8_ls>;
				cam-type = "IR_L";
				dser-link-port = "b";
				st-vc = <2>;
				vc-id = <0>;
				orbbec_cam_num = <1>;
				nvidia,gmsl-dser-device = <&dser0>;
				pps-gpios = <&gpio PPS_TRIGGER GPIO_ACTIVE_LOW>;
				ports {
					#address-cells = <1>;
					#size-cells = <0>;

					port@0 {
						reg = <0>;
						g2m1_2_out: endpoint {
							vc-id = <0>;
							port-index = <1>; //1
							bus-width = <2>;
							remote-endpoint = <&g2xx_csi_in6>;
						};
					};
				};
				mode0 {
					pixel_t = "grey_y8";
					num_lanes = "4";
					csi_pixel_bit_depth = "8";
					active_w = "1280";
					active_h = "720";
					tegra_sinterface = "serial_b";
					mclk_khz = "24000";
					pix_clk_hz = "750000000";
					serdes_pix_clk_hz = "750000000";
					discontinuous_clk = "no";
					dpcm_enable = "false";
					cil_settletime = "0";
					line_length = "1280";
					mclk_multiplier = "15.625";
					embedded_metadata_height = "1";
					vc_id = "0";
				};
			};
			g2m1_1: g2m1@6B {
				status = "okay";
				reg = <0x6B>;
				compatible = "orbbec,g3xx";
				use_sensor_mode_id = "true";
				vcc-supply = <&vdd_1v8_ls>;
				cam-type = "RGB";
				dser-link-port = "b";
				st-vc = <1>;
				vc-id = <3>;
				orbbec_cam_num = <1>;
				nvidia,gmsl-dser-device = <&dser0>;
				pps-gpios = <&gpio PPS_TRIGGER GPIO_ACTIVE_LOW>;
				ports {
					#address-cells = <1>;
					#size-cells = <0>;

					port@0 {
						reg = <0>;
						g2m1_1_out: endpoint {
							vc-id = <3>;
							port-index = <1>; //1
							bus-width = <2>;
							remote-endpoint = <&g2xx_csi_in5>;
						};
					};
				};
				mode0 {
					pixel_t = "yuv_yvyu16";
					num_lanes = "4";
					csi_pixel_bit_depth = "16";
					active_w = "1280";
					active_h = "720";
					tegra_sinterface = "serial_b";
					mclk_khz = "24000";
					pix_clk_hz = "375000000";
					serdes_pix_clk_hz = "375000000";
					discontinuous_clk = "no";
					dpcm_enable = "false";
					cil_settletime = "0";
					line_length = "1280";
					mclk_multiplier = "15.625";
					embedded_metadata_height = "1";
					vc_id = "3";
				};
			};
			g2m1_0: g2m0@6A {
				status = "okay";
				reg = <0x6A>;
				compatible = "orbbec,g3xx";
				use_sensor_mode_id = "true";
				vcc-supply = <&vdd_1v8_ls>;
				cam-type = "Depth";
				dser-link-port = "b";
				st-vc = <0>;
				vc-id = <2>;
				orbbec_cam_num = <1>;
				nvidia,gmsl-dser-device = <&dser0>;
				pps-gpios = <&gpio PPS_TRIGGER GPIO_ACTIVE_LOW>;
				ports {
					#address-cells = <1>;
					#size-cells = <0>;

					port@0 {
						reg = <0>;
						g2m1_0_out: endpoint {
							vc-id = <2>;
							port-index = <1>; //1
							bus-width = <2>;
							remote-endpoint = <&g2xx_csi_in4>;
						};
					};
				};
				mode0 {
					pixel_t = "yuv_yvyu16";
					num_lanes = "4";
					csi_pixel_bit_depth = "16";
					active_w = "1280";
					active_h = "720";
					tegra_sinterface = "serial_b";
					mclk_khz = "24000";
					pix_clk_hz = "375000000";
					serdes_pix_clk_hz = "375000000";
					discontinuous_clk = "no";
					dpcm_enable = "false";
					cil_settletime = "0";
					line_length = "1280";
					mclk_multiplier = "15.625";
					embedded_metadata_height = "1";
					vc_id = "2";
				};
			};

			g2m0_3: g2m3@69 {
				status = "okay";
				reg = <0x69>;
				compatible = "orbbec,g3xx";
				use_sensor_mode_id = "true";
				vcc-supply = <&vdd_1v8_ls>;
				cam-type = "IR_R";
				dser-link-port = "a";
				st-vc = <3>;
				vc-id = <3>;
				orbbec_cam_num = <0>;
				nvidia,gmsl-dser-device = <&dser0>;
				pps-gpios = <&gpio PPS_TRIGGER GPIO_ACTIVE_LOW>;
				ports {
					#address-cells = <1>;
					#size-cells = <0>;

					port@0 {
						reg = <0>;
						g2m0_3_out: endpoint {
							vc-id = <3>;
							port-index = <0>; //0
							bus-width = <2>;
							remote-endpoint = <&g2xx_csi_in3>;
						};
					};
				};
				mode0 {
					pixel_t = "grey_y8";
					num_lanes = "4";
					csi_pixel_bit_depth = "8";
					active_w = "1280";
					active_h = "720";
					tegra_sinterface = "serial_a";
					mclk_khz = "24000";
					pix_clk_hz = "750000000";
					serdes_pix_clk_hz = "750000000";
					discontinuous_clk = "no";
					dpcm_enable = "false";
					cil_settletime = "0";
					line_length = "1280";
					mclk_multiplier = "15.625";
					embedded_metadata_height = "1";
					vc_id = "3";
				};
			};
			g2m0_2: g2m2@68 {
				status = "okay";
				reg = <0x68>;
				compatible = "orbbec,g3xx";
				use_sensor_mode_id = "true";
				vcc-supply = <&vdd_1v8_ls>;
				cam-type = "IR_L";
				dser-link-port = "a";
				st-vc = <2>;
				vc-id = <2>;
				orbbec_cam_num = <0>;
				nvidia,gmsl-dser-device = <&dser0>;
				pps-gpios = <&gpio PPS_TRIGGER GPIO_ACTIVE_LOW>;
				ports {
					#address-cells = <1>;
					#size-cells = <0>;

					port@0 {
						reg = <0>;
						g2m0_2_out: endpoint {
							vc-id = <2>;
							port-index = <0>; //0
							bus-width = <2>;
							remote-endpoint = <&g2xx_csi_in2>;
						};
					};
				};
				mode0 {
					pixel_t = "grey_y8";
					num_lanes = "4";
					csi_pixel_bit_depth = "8";
					active_w = "1280";
					active_h = "720";
					tegra_sinterface = "serial_a";
					mclk_khz = "24000";
					pix_clk_hz = "750000000";
					serdes_pix_clk_hz = "750000000";
					discontinuous_clk = "no";
					dpcm_enable = "false";
					cil_settletime = "0";
					line_length = "1280";
					mclk_multiplier = "15.625";
					embedded_metadata_height = "1";
					vc_id = "2";
				};
			};
			g2m0_1: g2m1@67 {
				status = "okay";
				reg = <0x67>;
				compatible = "orbbec,g3xx";
				use_sensor_mode_id = "true";
				vcc-supply = <&vdd_1v8_ls>;
				cam-type = "RGB";
				dser-link-port = "a";
				st-vc = <1>;
				vc-id = <1>;
				orbbec_cam_num = <0>;
				nvidia,gmsl-dser-device = <&dser0>;
				pps-gpios = <&gpio PPS_TRIGGER GPIO_ACTIVE_LOW>;
				ports {
					#address-cells = <1>;
					#size-cells = <0>;

					port@0 {
						reg = <0>;
						g2m0_1_out: endpoint {
							vc-id = <1>;
							port-index = <0>; //0
							bus-width = <2>;
							remote-endpoint = <&g2xx_csi_in1>;
						};
					};
				};
				mode0 {
					pixel_t = "yuv_yvyu16";
					num_lanes = "4";
					csi_pixel_bit_depth = "16";
					active_w = "1280";
					active_h = "720";
					tegra_sinterface = "serial_a";
					mclk_khz = "24000";
					pix_clk_hz = "375000000";
					serdes_pix_clk_hz = "375000000";
					discontinuous_clk = "no";
					dpcm_enable = "false";
					cil_settletime = "0";
					line_length = "1280";
					mclk_multiplier = "15.625";
					embedded_metadata_height = "1"; 
					vc_id = "1";
				};
			};
			g2m0_0: g2m0@66 {
				status = "okay";
				reg = <0x66>;
				compatible = "orbbec,g3xx";
				use_sensor_mode_id = "true";
				vcc-supply = <&vdd_1v8_ls>;
				cam-type = "Depth";
				dser-link-port = "a";
				st-vc = <0>;   				/**< Default sensor virtual channel. */
				vc-id = <0>;				/**< Destination virtual channel (user-defined). */
				orbbec_cam_num = <0>;
				nvidia,gmsl-dser-device = <&dser0>;
				pps-gpios = <&gpio PPS_TRIGGER GPIO_ACTIVE_LOW>;
				ports {
					#address-cells = <1>;
					#size-cells = <0>;

					port@0 {
						reg = <0>;
						g2m0_0_out: endpoint {
							vc-id = <0>;
							port-index = <0>; //0
							bus-width = <2>;
							remote-endpoint = <&g2xx_csi_in0>;
						};
					};
				};
				mode0 {
					pixel_t = "yuv_yvyu16";
					num_lanes = "4";
					csi_pixel_bit_depth = "16";
					active_w = "1280";
					active_h = "720";
					tegra_sinterface = "serial_a";
					mclk_khz = "24000";
					pix_clk_hz = "375000000";
					serdes_pix_clk_hz = "375000000";
					discontinuous_clk = "no";
					dpcm_enable = "false";
					cil_settletime = "0";
					line_length = "1280";
					mclk_multiplier = "15.625";
					embedded_metadata_height = "1"; 
					vc_id = "0";
				};
			};

			dser0: max96712@29 {
				status = "okay";
				reg = <0x29>; //0x52>>1
				compatible = "maxim,max96712";
				index = <0>;
				csi-mode = "4x2"; //4*2lane
				seri-addr = <0x48>;
				proxy-addr = <0x20>;
				real-addr = <0x66>;
				reset-gpios = <&gpio CAM0_PWDN GPIO_ACTIVE_HIGH>;
				fsync_mfp_index = <2>;
				pps_mfp_index = <9>;
			};
		};
	};
};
